# MCF5441x register map
Vendor: NXP; File version: 1.0
Registers are 32-bit, read-write, reset 0x0 unless marked. A register's access mark holds for its fields unless they carry their own. Offsets are from the block's base; [hi:lo] are bit positions; {n}, {i} and the like mark numbered series.

## DMATIMER0
Base 0xFC070000
Same registers: DMATIMER1 0xFC074000, DMATIMER2 0xFC078000, DMATIMER3 0xFC07C000
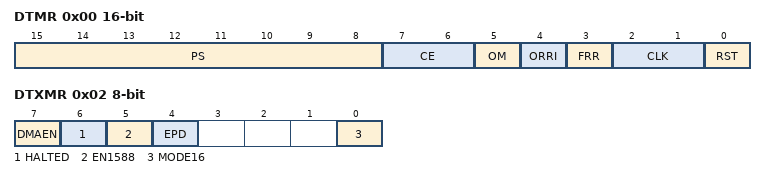
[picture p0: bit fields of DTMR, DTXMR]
0x00 DTMR 16-bit
  [15:8] PS
  [7:6] CE
  [5] OM
  [4] ORRI
  [3] FRR
  [2:1] CLK
  [0] RST
    0=RESET_TIMER_SOFTWARE_RESET; 1=ENABLE_TIMER
0x02 DTXMR 8-bit
  [7] DMAEN
    0=DISABLED; 1=ENABLED
  [6] HALTED
  [5] EN1588
  [4] EPD
    0=DISABLE; 1=ENABLE
  [0] MODE16
0x03 DTER 8-bit
  [1] REF
0x04 DTRR reset 0xFFFFFFFF
  [31:0] REF
0x08 DTCR
0x0C DTCN ro
  [31:0] CNT

## DSPI0
Base 0xFC05C000
Same registers: DSPI2 0xEC038000, DSPI3 0xEC03C000, DSPI1 0xFC03C000
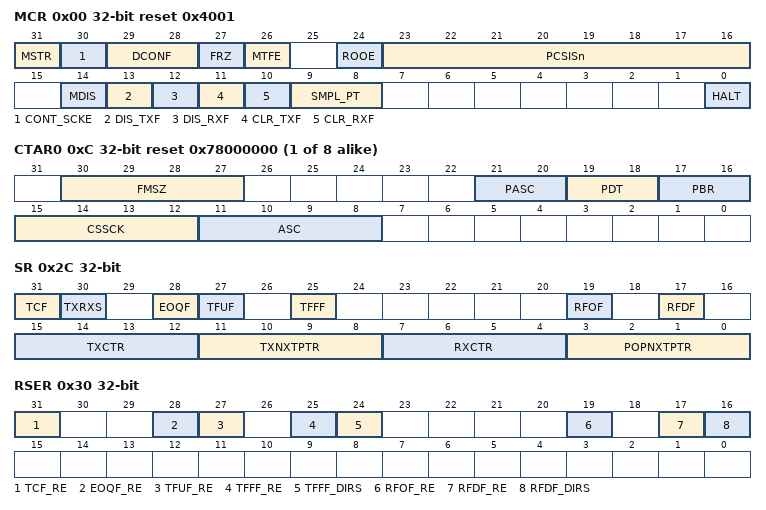
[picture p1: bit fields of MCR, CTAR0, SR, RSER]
0x00 MCR reset 0x4001
  [31] MSTR
    0=SLAVE_MODE; 1=MASTER_MODE
  [30] CONT_SCKE
    0=DISABLED; 1=ENABLED
  [29:28] DCONF
    0=SPI
  [27] FRZ
  [26] MTFE
  [24] ROOE
  [23:16] PCSISn
  [14] MDIS
  [13] DIS_TXF
    0=ENABLED; 1=DISABLED
  [12] DIS_RXF
    0=ENABLED; 1=DISABLED
  [11] CLR_TXF
  [10] CLR_RXF
  [9:8] SMPL_PT
  [0] HALT
    0=START_TRANSFERS; 1=STOP_TRANSFERS
0x08 TCR
  [31:16] SPI_TCNT
{0xC+4i} CTAR{i} reset 0x78000000 (i=0..7)
  [30:27] FMSZ, [21:20] PASC, [19:18] PDT, [17:16] PBR, [15:12] CSSCK, [11:8] ASC
0x2C SR
  [31] TCF write-1-clears
    0=NOT_COMPLETE; 1=COMPLETE
  [30] TXRXS
  [28] EOQF write-1-clears
  [27] TFUF write-1-clears
  [25] TFFF write-1-clears
    0=FULL; 1=NOT_FULL
  [19] RFOF write-1-clears
  [17] RFDF write-1-clears
    0=EMPTY; 1=NOT_EMPTY
  [15:12] TXCTR
  [11:8] TXNXTPTR
  [7:4] RXCTR
  [3:0] POPNXTPTR
0x30 RSER
  [31] TCF_RE, [28] EOQF_RE, [27] TFUF_RE, [25] TFFF_RE, [24] TFFF_DIRS, [19] RFOF_RE, [17] RFDF_RE, [16] RFDF_DIRS
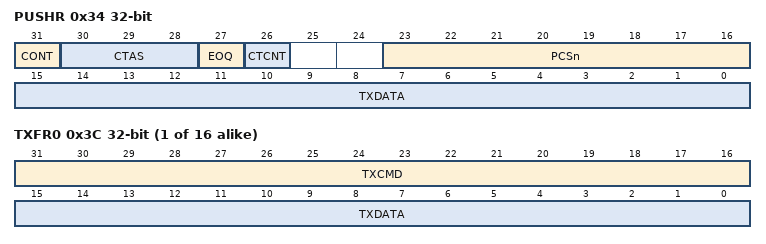
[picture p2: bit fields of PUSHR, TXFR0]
0x34 PUSHR
  [31] CONT
  [30:28] CTAS
    0=CTAR0; 1=CTAR1; 2=CTAR2; 4=CTAR4; 5=CTAR5
  [27] EOQ
  [26] CTCNT
  [23:16] PCSn
  [15:0] TXDATA
0x38 POPR ro
  [15:0] RXDATA
{0x3C+4i} TXFR{i} ro (i=0..15)
  [31:16] TXCMD, [15:0] TXDATA
{0x7C+4i} RXFR{i} ro (i=0..15)
  [15:0] RXDATA

## EDMA
Base 0xFC044000
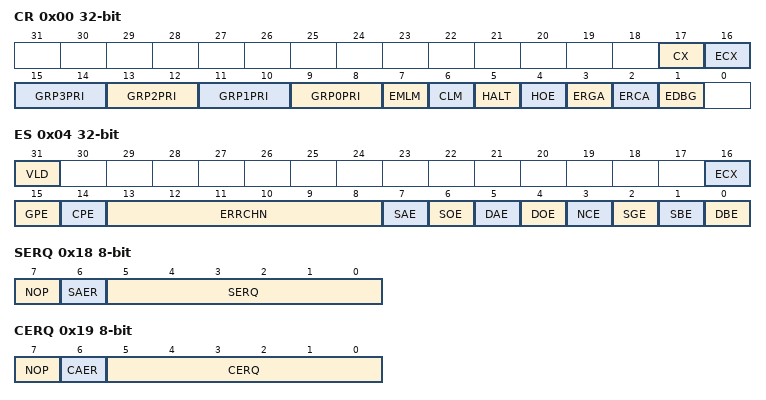
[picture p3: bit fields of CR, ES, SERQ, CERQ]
0x00 CR
  [17] CX, [16] ECX, [2n+9:2n+8] GRP{n}PRI (n=0..3), [7] EMLM, [6] CLM, [5] HALT, [4] HOE, [3] ERGA, [2] ERCA, [1] EDBG
0x04 ES ro
  [31] VLD, [16] ECX, [15] GPE, [14] CPE, [13:8] ERRCHN, [7] SAE, [6] SOE, [5] DAE, [4] DOE, [3] NCE, [2] SGE, [1] SBE, [0] DBE
0x08 ERQH
0x0C ERQL
  [31:0] ERQn
0x10 EEIH
0x14 EEIL
0x18 SERQ 8-bit wo
  [7] NOP, [6] SAER, [5:0] SERQ
0x19 CERQ 8-bit wo
  [7] NOP, [6] CAER, [5:0] CERQ
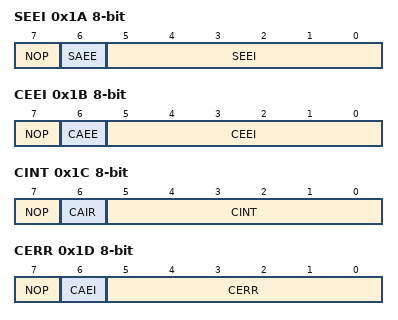
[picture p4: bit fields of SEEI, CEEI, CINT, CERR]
0x1A SEEI 8-bit wo
  [7] NOP, [6] SAEE, [5:0] SEEI
0x1B CEEI 8-bit wo
  [7] NOP, [6] CAEE, [5:0] CEEI
0x1C CINT 8-bit wo
  [7] NOP, [6] CAIR, [5:0] CINT
0x1D CERR 8-bit wo
  [7] NOP, [6] CAEI, [5:0] CERR
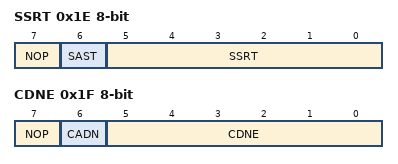
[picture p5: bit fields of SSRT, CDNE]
0x1E SSRT 8-bit wo
  [7] NOP, [6] SAST, [5:0] SSRT
0x1F CDNE 8-bit wo
  [7] NOP, [6] CADN, [5:0] CDNE
0x20 INTH
0x24 INTL
  [31:0] INTn write-1-clears
0x28 ERRH
0x2C ERRL
  [31:0] ERRn write-1-clears
0x30 RSH
0x34 RSL
  [31:0] HRSn write-1-clears
{0x100+i} DCHPRI{i} 8-bit reset not defined (i=0..63)

## EPORT
Base 0xFC090000
0x00 EPPAR 16-bit
0x03 EPIER 8-bit
  [7:0] EPIEn
0x06 EPFR 8-bit
  [7:0] EPFn write-1-clears

## ESDHC
Base 0xFC0CC000
0x00 DSADDR
  [31:0] DS_ADDR
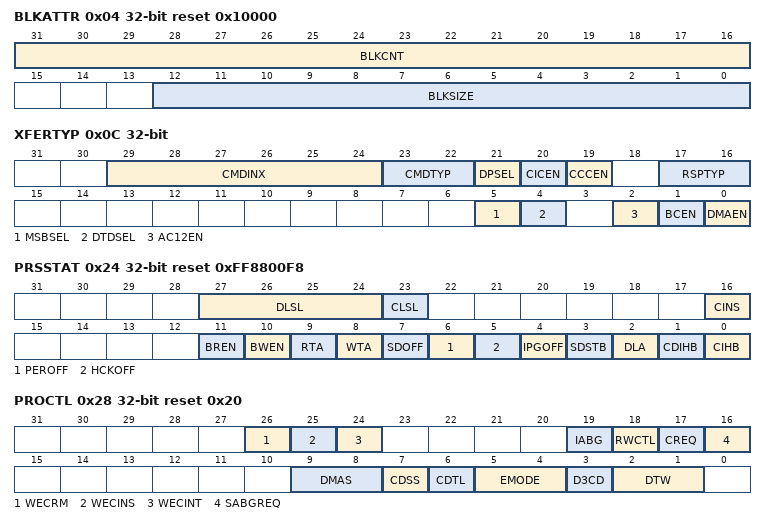
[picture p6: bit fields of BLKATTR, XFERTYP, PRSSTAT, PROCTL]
0x04 BLKATTR reset 0x10000
  [31:16] BLKCNT, [12:0] BLKSIZE
0x08 CMDARG
0x0C XFERTYP
  [29:24] CMDINX
  [23:22] CMDTYP
  [21] DPSEL
    0=NO_DATA_PRESENT; 1=DATA_PRESENT
  [20] CICEN
  [19] CCCEN
  [17:16] RSPTYP
  [5] MSBSEL
    0=SINGLE_BLOCK; 1=MULTIPLE_BLOCKS
  [4] DTDSEL
    0=WRITE_HOST_TO_CARD; 1=READ_CARD_TO_HOST
  [2] AC12EN
    0=DISABLE; 1=ENABLE
  [1] BCEN
    0=DISABLE; 1=ENABLE
  [0] DMAEN
    0=DISABLE; 1=ENABLE
{0x10+4i} CMDRSP{i} ro (i=0..3)
0x20 DATPORT
  [31:0] DATCONT
0x24 PRSSTAT ro reset 0xFF8800F8
  [27:24] DLSL
  [23] CLSL
  [16] CINS
  [11] BREN
    0=DISABLE; 1=ENABLE
  [10] BWEN
    0=DISABLE; 1=ENABLE
  [9] RTA
    0=NO_VALID_DATA; 1=TRANSFERRING_DATA
  [8] WTA
    0=NO_VALID_DATA; 1=TRANSFERRING_DATA
  [7] SDOFF
    0=ACTIVE; 1=GATED_OFF
  [6] PEROFF
  [5] HCKOFF
  [4] IPGOFF
  [3] SDSTB
  [2] DLA
    0=INACTIVE; 1=ACTIVE
  [1] CDIHB
  [0] CIHB
0x28 PROCTL reset 0x20
  [26] WECRM
    0=DISABLE; 1=ENABLE
  [25] WECINS
    0=DISABLE; 1=ENABLE
  [24] WECINT
    0=DISABLE; 1=ENABLE
  [19] IABG
  [18] RWCTL
  [17] CREQ
    0=NO_EFFECT; 1=RESTART
  [16] SABGREQ
    0=TRANSFER; 1=STOP_OR_NOT_RESUME_YET
  [9:8] DMAS
    0=SIMPLE_DMA; 1=ADVANCED_DMA_1_ADMA1; 2=ADVANCED_DMA_2_ADMA2
  [7] CDSS
  [6] CDTL
    0=NO_CARD_IN_THE_SLOT; 1=CARD_IS_INSERTED
  [5:4] EMODE
  [3] D3CD
  [2:1] DTW
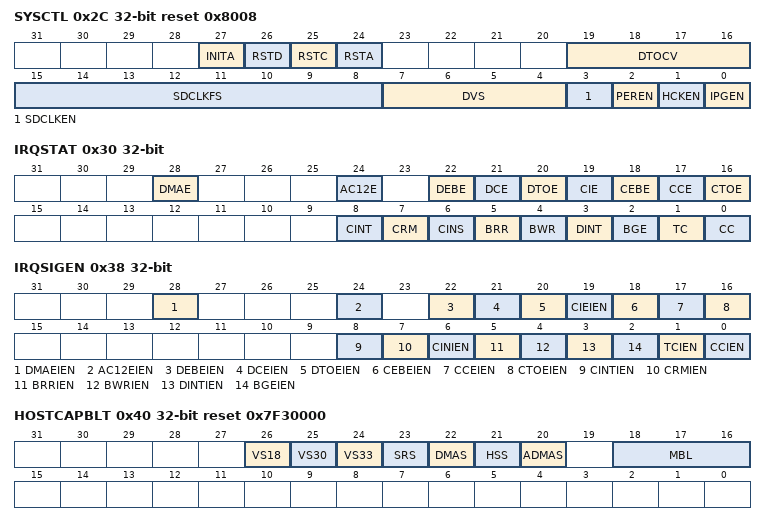
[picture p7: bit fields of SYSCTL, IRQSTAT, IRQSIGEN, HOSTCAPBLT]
0x2C SYSCTL reset 0x8008
  [27] INITA
  [26] RSTD
    0=WORK; 1=RESET
  [25] RSTC
    0=WORK; 1=RESET
  [24] RSTA
    0=WORK; 1=RESET
  [19:16] DTOCV
  [15:8] SDCLKFS
  [7:4] DVS
  [3] SDCLKEN
    0=DISABLED; 1=ENABLED
  [2] PEREN
  [1] HCKEN
  [0] IPGEN
0x30 IRQSTAT
  [28] DMAE write-1-clears
    0=NO_ERROR; 1=ERROR
  [24] AC12E write-1-clears
    0=NO_ERROR; 1=ERROR
  [22] DEBE write-1-clears
    0=NO_ERROR; 1=ERROR
  [21] DCE write-1-clears
    0=NO_ERROR; 1=ERROR
  [20] DTOE write-1-clears
    0=NO_ERROR; 1=TIMEOUT
  [19] CIE write-1-clears
    0=NO_ERROR; 1=TIMEOUT
  [18] CEBE write-1-clears
    0=NO_ERROR; 1=END_BIT_ERROR_GENERATED
  [17] CCE write-1-clears
    0=NO_ERROR; 1=CRC_ERROR_GENERATED
  [16] CTOE write-1-clears
    0=NO_ERROR; 1=TIME_OUT
  [8] CINT write-1-clears
    0=NO_CARD_INTERRUPT; 1=GENERATE_CARD_INTERRUPT
  [7] CRM write-1-clears
  [6] CINS write-1-clears
  [5] BRR write-1-clears
    0=NOT_READY_TO_READ_BUFFER; 1=READY_TO_READ_BUFFER
  [4] BWR write-1-clears
  [3] DINT write-1-clears
    0=NO_DMA_INTERRUPT; 1=DMA_INTERRUPT_IS_GENERATED
  [2] BGE write-1-clears
  [1] TC write-1-clears
  [0] CC write-1-clears
    0=NO_COMMAND_COMPLETE; 1=COMMAND_COMPLETE
0x34 IRQSTATEN reset 0x117F013F
0x38 IRQSIGEN
  [all] fields
    0=MASKED; 1=ENABLED
  [28] DMAEIEN
  [24] AC12EIEN
  [22] DEBEIEN
  [21] DCEIEN
  [20] DTOEIEN
  [19] CIEIEN
  [18] CEBEIEN
  [17] CCEIEN
  [16] CTOEIEN
  [8] CINTIEN
  [7] CRMIEN
  [6] CINIEN
  [5] BRRIEN
  [4] BWRIEN
  [3] DINTIEN
  [2] BGEIEN
  [1] TCIEN
  [0] CCIEN
0x3C AUTOC12ERR ro
0x40 HOSTCAPBLT ro reset 0x7F30000
  [26] VS18
  [25] VS30
  [24] VS33
  [23] SRS
    0=NOT_SUPPORTED; 1=SUPPORTED
  [22] DMAS
    0=NOT_SUPPORTED; 1=SUPPORTED
  [21] HSS
    0=NOT_SUPPORTED; 1=SUPPORTED
  [20] ADMAS
  [18:16] MBL
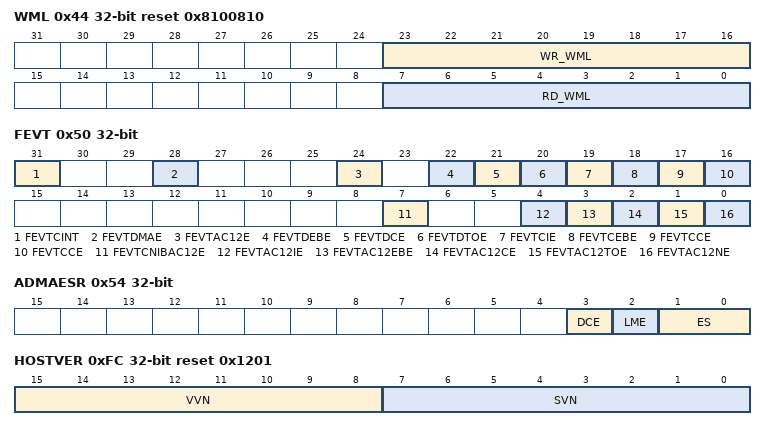
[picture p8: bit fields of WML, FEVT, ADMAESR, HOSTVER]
0x44 WML reset 0x8100810
  [23:16] WR_WML, [7:0] RD_WML
0x50 FEVT wo
  [31] FEVTCINT, [28] FEVTDMAE, [24] FEVTAC12E, [22] FEVTDEBE, [21] FEVTDCE, [20] FEVTDTOE, [19] FEVTCIE, [18] FEVTCEBE, [17] FEVTCCE, [16] FEVTCCE, [7] FEVTCNIBAC12E, [4] FEVTAC12IE, [3] FEVTAC12EBE, [2] FEVTAC12CE, [1] FEVTAC12TOE, [0] FEVTAC12NE
0x54 ADMAESR ro
  [3] DCE
    0=NO_ERROR; 1=ERROR
  [2] LME
  [1:0] ES
0x58 ADMASAR
  [31:2] ADDR
0xC0 VENDOR reset 0x1
  [0] EXT_DMA_EN
0xFC HOSTVER ro reset 0x1201
  [15:8] VVN, [7:0] SVN
